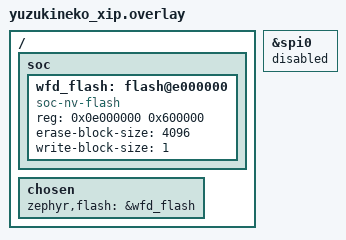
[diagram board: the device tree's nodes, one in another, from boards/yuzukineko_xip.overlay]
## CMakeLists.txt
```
# SPDX-License-Identifier: Apache-2.0
cmake_minimum_required(VERSION 3.20.0)
list(APPEND ZEPHYR_EXTRA_MODULES ${CMAKE_CURRENT_SOURCE_DIR}/../..
     ${CMAKE_CURRENT_SOURCE_DIR}/../../../aic8800)
find_package(Zephyr REQUIRED HINTS $ENV{ZEPHYR_BASE})
project(miracast_receiver)
target_sources(app PRIVATE src/main.c)
```

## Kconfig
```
# SPDX-License-Identifier: Apache-2.0
mainmenu "Miracast receiver"

config SAMPLE_WFD_NAME
	string "Wi-Fi Display device name"
	default "YuzukiNeko Miracast"

config SAMPLE_WFD_720P
	bool "Also advertise 1280x720p30"
	default n
	help
	  Requires enough memory for the decoder surfaces and sufficient network
	  throughput. The mandatory 640x480p60 timing is always advertised.

config SAMPLE_WFD_PEER
	string "Source IPv4 address for an existing IP link (empty = Wi-Fi Direct)"
	default ""
	help
	  Useful for transport testing on a preconfigured interface. This skips
	  P2P startup. The source must implement Wi-Fi Display RTSP on port 7236.

source "Kconfig.zephyr"
```

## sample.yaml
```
sample:
  name: Miracast Wi-Fi Display receiver
tests:
  sample.miracast.receiver:
    build_only: true
    platform_allow:
      - yuzukineko
    tags:
      - net
      - wifi
      - display
```

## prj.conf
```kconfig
CONFIG_MIRACAST=y
CONFIG_MIRACAST_PLAYER=y
CONFIG_AIC8800=y
CONFIG_AIC8800_P2P_WFD=y
CONFIG_MINIMAL_LIBC=y
CONFIG_COMMON_LIBC_MALLOC_ARENA_SIZE=-1
CONFIG_HEAP_MEM_POOL_SIZE=262144
CONFIG_MAIN_STACK_SIZE=8192
CONFIG_MAIN_THREAD_PRIORITY=8
CONFIG_SYSTEM_WORKQUEUE_STACK_SIZE=4096
CONFIG_NET_MGMT_EVENT_STACK_SIZE=4096
CONFIG_FPU=y
CONFIG_FPU_SHARING=y
CONFIG_SPEED_OPTIMIZATIONS=y
CONFIG_LOG=y
CONFIG_LOG_PRINTK=n
CONFIG_PRINTK=y
CONFIG_SHELL=n
CONFIG_DEVMEM_SHELL=n
CONFIG_THREAD_NAME=y

CONFIG_NETWORKING=y
CONFIG_NET_IPV4=y
CONFIG_NET_IPV6=n
CONFIG_NET_UDP=y
CONFIG_NET_TCP=y
CONFIG_NET_SOCKETS=y
CONFIG_NET_DHCPV4_SERVER_ADDR_COUNT=1
CONFIG_NET_PKT_RX_COUNT=64
CONFIG_NET_PKT_TX_COUNT=64
CONFIG_NET_BUF_RX_COUNT=256
CONFIG_NET_BUF_TX_COUNT=256
CONFIG_NET_BUF_DATA_SIZE=1536
CONFIG_NET_TCP_MAX_SEND_WINDOW_SIZE=16384
CONFIG_NET_TCP_MAX_RECV_WINDOW_SIZE=16384
CONFIG_ZVFS_OPEN_MAX=32
CONFIG_ZVFS_POLL_MAX=8
# The current SoC port has no hardware RNG driver.
CONFIG_TEST_RANDOM_GENERATOR=y

CONFIG_DISPLAY=y
CONFIG_DISPLAY_SUNXI_ARGB8888=y
CONFIG_VDEC=y
CONFIG_I2S=y
CONFIG_AUDIO=y
CONFIG_AUDIO_CODEC=y
CONFIG_DMA=y
CONFIG_LVGL=y
CONFIG_LV_COLOR_DEPTH_32=y
CONFIG_LV_Z_MEM_POOL_SIZE=65536
CONFIG_LV_Z_VDB_SIZE=4
CONFIG_LV_Z_SHELL=n
CONFIG_LV_FONT_MONTSERRAT_20=y
CONFIG_LV_USE_LABEL=y

CONFIG_G2D=n
CONFIG_ADC=n
CONFIG_SPI=n
CONFIG_MIPI_DBI=n
CONFIG_WDT_SUNXI=n
CONFIG_USB_PHY_SUNXI=n
```

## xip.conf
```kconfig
# SPDX-License-Identifier: Apache-2.0
CONFIG_XIP=y
```

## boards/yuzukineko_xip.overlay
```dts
/* SPDX-License-Identifier: Apache-2.0 */
/ {
	soc {
		wfd_flash: flash@e000000 {
			compatible = "soc-nv-flash";
			reg = <0x0e000000 0x600000>;
			erase-block-size = <4096>;
			write-block-size = <1>;
		};
	};
	chosen {
		zephyr,flash = &wfd_flash;
	};
};

/* The SPIF window uses these pins throughout execution. */
&spi0 {
	status = "disabled";
};
```

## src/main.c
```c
/* SPDX-License-Identifier: Apache-2.0 */
#include <errno.h>
#include <string.h>
#include <lvgl.h>
#include <zephyr/drivers/display.h>
#include <zephyr/kernel.h>
#include <zephyr/sys/atomic.h>
#include <zephyr/sys/printk.h>
#include <aic8800/p2p.h>
#include <miracast/player.h>

static atomic_t session_state = ATOMIC_INIT(MIRACAST_CLOSED);

static void state(void *ctx, enum miracast_state value)
{
	ARG_UNUSED(ctx);
	atomic_set(&session_state, value);
}

static void text(lv_obj_t *label, const char *message)
{
	lv_label_set_text(label, message);
	lv_obj_center(label);
	lv_timer_handler();
}

int main(void)
{
	const struct device *display = DEVICE_DT_GET(DT_CHOSEN(zephyr_display));
	char peer[16];

	if (!device_is_ready(display) || !device_is_ready(DEVICE_DT_GET(DT_NODELABEL(ve))) ||
	    !device_is_ready(DEVICE_DT_GET(DT_NODELABEL(audio_codec))) ||
	    !device_is_ready(DEVICE_DT_GET(DT_NODELABEL(codec_analog)))) {
		printk("Miracast: display, decoder or audio device is not ready\n");
		return -ENODEV;
	}
	lv_obj_set_style_bg_opa(lv_screen_active(), LV_OPA_TRANSP, 0);
	lv_obj_t *label = lv_label_create(lv_screen_active());

	lv_obj_set_style_text_font(label, &lv_font_montserrat_20, 0);
	lv_obj_set_style_text_color(label, lv_color_white(), 0);
	lv_obj_set_style_bg_color(label, lv_color_black(), 0);
	lv_obj_set_style_bg_opa(label, LV_OPA_COVER, 0);
	lv_obj_set_style_pad_all(label, 24, 0);
	lv_obj_set_style_text_align(label, LV_TEXT_ALIGN_CENTER, 0);
	display_blanking_off(display);
	printk("Miracast receiver: %s\n", CONFIG_SAMPLE_WFD_NAME);

	while (true) {
		bool direct = !CONFIG_SAMPLE_WFD_PEER[0];
		int ret;

		text(label, "Starting Miracast...");
		if (direct) {
			ret = aic8800_p2p_start(CONFIG_SAMPLE_WFD_NAME, 7236);
			if (ret) {
				printk("Miracast: P2P start failed: %d\n", ret);
				text(label, "Wi-Fi Direct could not start. See serial log.");
				return ret;
			}
			printk("Miracast: discoverable; select '%s' on the phone\n", CONFIG_SAMPLE_WFD_NAME);
			text(label, CONFIG_SAMPLE_WFD_NAME "\n\nOpen Wireless display / Screen mirroring\non your Android phone and select this display.");
			int64_t last_pbc = k_uptime_get();

			while ((ret = aic8800_p2p_peer(peer, sizeof(peer))) == -EAGAIN) {
				/* The running receiver is an explicit invitation to pair. */
				if (k_uptime_get() - last_pbc >= 100000) {
					aic8800_p2p_accept();
					last_pbc = k_uptime_get();
				}
				lv_timer_handler();
				k_msleep(20);
			}
			if (ret) {
				aic8800_p2p_stop();
				printk("Miracast: peer discovery failed: %d\n", ret);
				return ret;
			}
		} else {
			if (strlen(CONFIG_SAMPLE_WFD_PEER) >= sizeof(peer)) return -EINVAL;
			strcpy(peer, CONFIG_SAMPLE_WFD_PEER);
		}
		printk("Miracast: source %s\n", peer);
		struct miracast_receiver_config config = {
			.peer = peer,
			.stream = {.rtp_port = 19000, .cea_modes = IS_ENABLED(CONFIG_SAMPLE_WFD_720P) ? 0x21 : 1},
			.ops = {.media = miracast_player_media, .state = state},
		};
		/* Some sources begin listening shortly after obtaining their address. */
		bool played = false;
		for (int attempt = 0; attempt < 10 && !played; attempt++) {
			text(label, "Connecting to the phone...");
			atomic_set(&session_state, MIRACAST_NEGOTIATING);
			ret = miracast_player_start(15);
			if (!ret) {
				ret = miracast_receiver_start(&config);
			}
			if (ret) {
				miracast_player_stop();
				printk("Miracast: receiver start: %d\n", ret);
				break;
			}
			unsigned last = 0;
			int64_t last_stats = k_uptime_get();

			while (miracast_receiver_running()) {
				if (atomic_get(&session_state) == MIRACAST_PLAYING) played = true;
				if (miracast_player_frames()) lv_obj_add_flag(label, LV_OBJ_FLAG_HIDDEN);
				if (k_uptime_get() - last_stats >= 5000) {
					unsigned n = miracast_player_frames();

					printk("Miracast: %u frames (+%u / 5 s)\n", n, n - last);
					last = n;
					last_stats = k_uptime_get();
				}
				lv_timer_handler();
				k_msleep(10);
			}
			miracast_receiver_stop();
			miracast_player_stop();
			lv_obj_remove_flag(label, LV_OBJ_FLAG_HIDDEN);
			k_msleep(500);
		}
		if (direct) aic8800_p2p_stop();
		text(label, "Disconnected. Preparing to receive again...");
		k_msleep(1000);
	}
	return 0;
}
```
